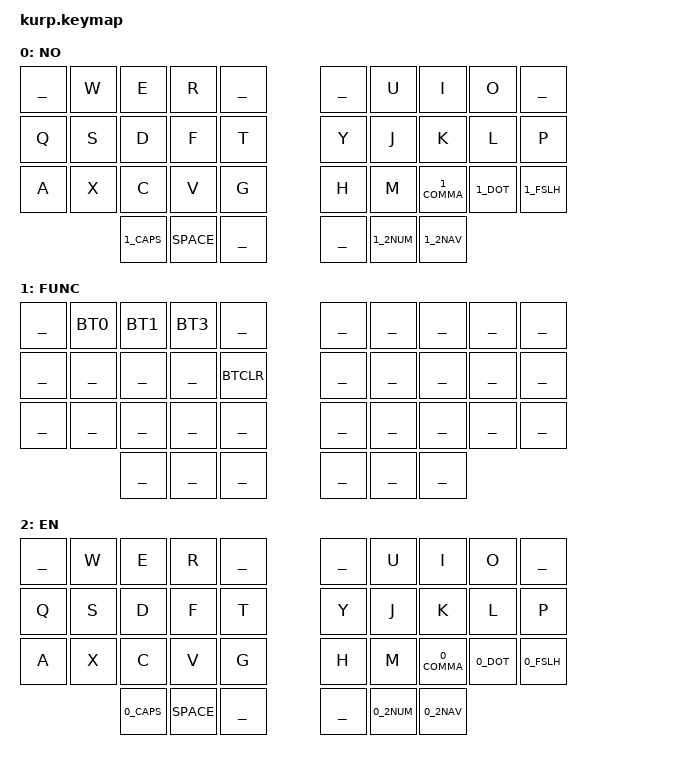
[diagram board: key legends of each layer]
// Copyright (c) 2023 The ZMK Contributors
// SPDX-License-Identifier: MiT

#include <behaviors.dtsi>
#include <dt-bindings/zmk/keys.h>
#include <dt-bindings/zmk/bt.h>
#include <dt-bindings/zmk/outputs.h>

#define HOST_OS 2

#include "keymap/kurp.h"
#include "keymap/helper.h"
#include "keymap/qwerty.h"
#include "keymap/1234.h"
#include "keymap/navigate.h"
#include "keymap/function.h"
#include "keymap/thumbs.h"
#include "keymap/combos.h"

ZMK_LAYER(NO,
//  ╭────────┬────────┬────────┬────────┬────────╮ ╭────────┬────────┬────────┬────────┬────────╮
      _        _W       _E       _R       _          _        _U       _I       _O       _
      _Q       _S       _D       _F       _T         _Y       _J       _K       _L       _P
      _A       _X       _C       _V       _G         _H       _M       _1_COMMA _1_DOT   _1_FSLH
//  ╰────────┴────────┼────────┼────────┼────────┤ ├────────┼────────┼────────┼────────┴────────╯
                        _1_CAPS  _SPACE   _          _        _1_2NUM  _1_2NAV
)

ZMK_LAYER(NO-NUM,
//  ╭────────┬────────┬────────┬────────┬────────╮ ╭────────┬────────┬────────┬────────┬────────╮
      _        _1_AT    _1_LBRC  _1_RBRC  _         _         _N7      _N8      _N9     _
      _1_EXCL  _1_DQT   _1_LPAR  _1_RPAR  _1_EQUAL  _1_PLUS   _N4      _N5      _N6     _
      _1_STAR  _1_CARET _1_LBKT  _1_RBKT  _1_DOLLAR _1_MINUS  _N1      _N2      _N3     _
//  ╰────────┴────────┼────────┼────────┼────────┤ ├────────┼────────┼────────┼────────┴────────╯
                        _        _        _          _        _        _
)

ZMK_LAYER(NO-NAV,
//  ╭────────┬────────┬────────┬────────┬────────╮ ╭────────┬────────┬────────┬────────┬────────╮
      _        _1_PARA  _1_LDANG _1_RDANG _          _        _PG_DN   _PG_UP   _END     _
      _1_PIPE  _1_SQT   _1_LT    _1_GT    _1_QMARK   _HOME    _DOWN    _UP      _RIGHT   _PSCRN
      _1_HASH  _1_TILDE _1_GRAVE _1_ACUTE _1_AMPS    _LEFT    _LSHIFT  _LCTRL   _LALT    _RALT
//  ╰────────┴────────┼────────┼────────┼────────┤ ├────────┼────────┼────────┼────────┴────────╯
                        _        _        _          _        _1_2ROOT _
)

ZMK_LAYER(FUNC,
//  ╭────────┬────────┬────────┬────────┬────────╮ ╭────────┬────────┬────────┬────────┬────────╮
      _        _BT0     _BT1     _BT3     _          _        _        _        _        _
      _        _        _        _        _BTCLR     _        _        _        _        _
      _        _        _        _        _          _        _        _        _        _
//  ╰────────┴────────┼────────┼────────┼────────┤ ├────────┼────────┼────────┼────────┴────────╯
                        _        _        _          _        _        _
)

ZMK_LAYER(EN,
//  ╭────────┬────────┬────────┬────────┬────────╮ ╭────────┬────────┬────────┬────────┬────────╮
      _        _W       _E       _R       _          _        _U       _I       _O       _
      _Q       _S       _D       _F       _T         _Y       _J       _K       _L       _P
      _A       _X       _C       _V       _G         _H       _M       _0_COMMA _0_DOT   _0_FSLH
//  ╰────────┴────────┼────────┼────────┼────────┤ ├────────┼────────┼────────┼────────┴────────╯
                        _0_CAPS  _SPACE   _          _        _0_2NUM  _0_2NAV
)

ZMK_LAYER(EN-NUM,
//  ╭────────┬────────┬────────┬────────┬────────╮ ╭────────┬────────┬────────┬────────┬────────╮
      _        _0_AT    _0_LBRC  _0_RBRC  _          _        _N7      _N8      _N9     _
      _0_EXCL  _0_DQT   _0_LPAR  _0_RPAR  _0_EQUAL  _0_PLUS  _N4      _N5      _N6     _
      _0_STAR  _0_CARET _0_LBKT  _0_RBKT  _0_DOLLAR  _0_MINUS _N1      _N2      _N3     _
//  ╰────────┴────────┼────────┼────────┼────────┤ ├────────┼────────┼────────┼────────┴────────╯
                        _        _        _          _        _        _
)

ZMK_LAYER(EN-NAV,
//  ╭────────┬────────┬────────┬────────┬────────╮ ╭────────┬────────┬────────┬────────┬────────╮
      _        _0_PARA  _0_LDANG _0_RDANG _          _        _PG_DN   _PG_UP   _END     _
      _0_PIPE  _0_SQT   _0_LT    _0_GT    _0_QMARK   _HOME    _DOWN    _UP      _RIGHT   _PSCRN
      _0_HASH  _0_TILDE _0_GRAVE _0_HASH2 _0_AMPS    _LEFT    _LSHIFT  _LCTRL   _LALT    _RALT
//  ╰────────┴────────┼────────┼────────┼────────┤ ├────────┼────────┼────────┼────────┴────────╯
                        _        _        _          _        _0_2ROOT _
)
